# nrf9230_engb_flpr register map
Vendor: Nordic Semiconductor; Series: nRF92; File version: 1
Registers are 32-bit, read-write, reset 0x0 unless marked. A register's access mark holds for its fields unless they carry their own. Offsets are from the block's base; [hi:lo] are bit positions; {n}, {i} and the like mark numbered series; 'fields as' and 'values as' point back to an identical list.

## GLOBAL_WDT131 — Watchdog Timer 0
Base 0x5F92B000
Same registers: GLOBAL_WDT132 0x5F92C000
0x00 TASKS_START wo — Start WDT
  [0] TASKS_START
    1=Trigger task
0x04 TASKS_STOP wo — Stop WDT
  [0] TASKS_STOP
    1=Trigger task
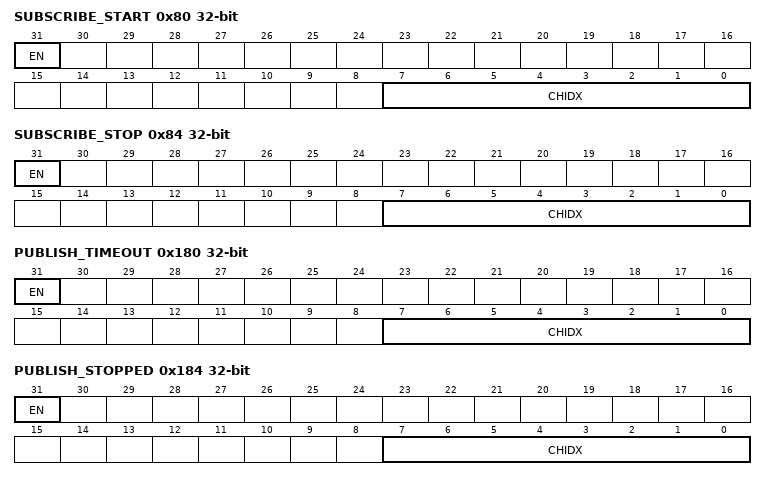
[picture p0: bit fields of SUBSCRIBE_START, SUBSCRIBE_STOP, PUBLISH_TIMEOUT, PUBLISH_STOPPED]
0x80 SUBSCRIBE_START — Subscribe configuration for task START
  [31] EN
    0=Disabled (Disable subscription); 1=Enabled (Enable subscription)
  [7:0] CHIDX — DPPI channel that task START will subscribe to
0x84 SUBSCRIBE_STOP — Subscribe configuration for task STOP
  [31] EN
    values as SUBSCRIBE_START.EN
  [7:0] CHIDX — DPPI channel that task STOP will subscribe to
0x100 EVENTS_TIMEOUT — Watchdog timeout
  [0] EVENTS_TIMEOUT
    0=NotGenerated (Event not generated); 1=Generated (Event generated)
0x104 EVENTS_STOPPED — Watchdog stopped
  [0] EVENTS_STOPPED
    values as EVENTS_TIMEOUT.EVENTS_TIMEOUT
0x180 PUBLISH_TIMEOUT — Publish configuration for event TIMEOUT
  [31] EN
    0=Disabled (Disable publishing); 1=Enabled (Enable publishing)
  [7:0] CHIDX — DPPI channel that event TIMEOUT will publish to
0x184 PUBLISH_STOPPED — Publish configuration for event STOPPED
  [31] EN
    values as PUBLISH_TIMEOUT.EN
  [7:0] CHIDX — DPPI channel that event STOPPED will publish to
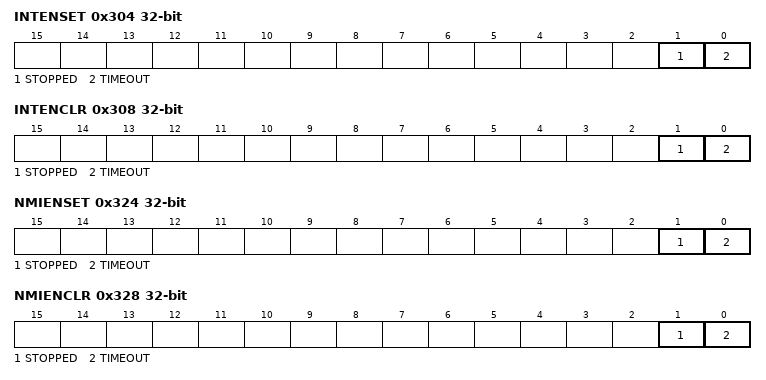
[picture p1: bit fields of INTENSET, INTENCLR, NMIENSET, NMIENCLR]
0x304 INTENSET — Enable interrupt
  [1] STOPPED — Write '1' to enable interrupt for event STOPPED
    on read: 0=Disabled (Read: Disabled); 1=Enabled (Read: Enabled) | on write: 1=Set (Enable)
  [0] TIMEOUT — Write '1' to enable interrupt for event TIMEOUT
    values as STOPPED
0x308 INTENCLR — Disable interrupt
  [1] STOPPED — Write '1' to disable interrupt for event STOPPED
    on read: 0=Disabled (Read: Disabled); 1=Enabled (Read: Enabled) | on write: 1=Clear (Disable)
  [0] TIMEOUT — Write '1' to disable interrupt for event TIMEOUT
    values as STOPPED
0x324 NMIENSET — Enable interrupt
  fields as INTENSET
0x328 NMIENCLR — Disable interrupt
  fields as INTENCLR
0x400 RUNSTATUS ro
  [0] RUNSTATUSWDT — Indicates whether or not WDT is running
    0=NotRunning (Watchdog is not running); 1=Running (Watchdog is running)
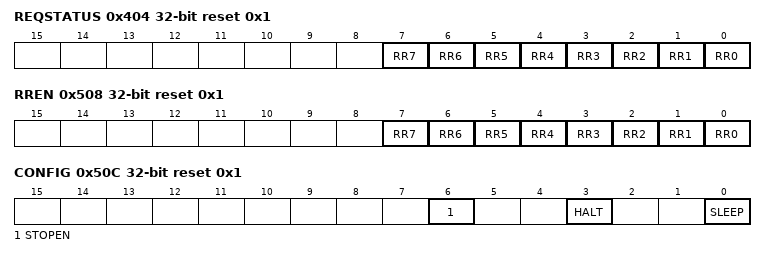
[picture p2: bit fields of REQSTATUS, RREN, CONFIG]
0x404 REQSTATUS ro reset 0x1 — Request status
  [n] RR{n} (n=0..7) — Request status for RR[{n}] register
    0=DisabledOrRequested (RR[{n}] register is not enabled, or are already requesting reload); 1=EnabledAndUnrequested (RR[{n}] register is enabled, and are not yet requesting reload)
0x504 CRV reset 0xFFFFFFFF — Counter reload value
  [31:0] CRV — Counter reload value in number of cycles of the 32.768 kHz clock
0x508 RREN reset 0x1 — Enable register for reload request registers
  [n] RR{n} (n=0..7) — Enable or disable RR[{n}] register
    0=Disabled (Disable RR[{n}] register); 1=Enabled (Enable RR[{n}] register)
0x50C CONFIG reset 0x1 — Configuration register
  [6] STOPEN — Allow stopping WDT
    0=Disable (Do not allow stopping WDT); 1=Enable (Allow stopping WDT)
  [3] HALT — Configure WDT to either be paused, or kept running, while the CPU is halted by the debugger
    0=Pause WDT while the CPU is halted by the debugger; 1=Run (Keep WDT running while the CPU is halted by the debugger)
  [0] SLEEP — Configure WDT to either be paused, or kept running, while the CPU is sleeping
    0=Pause WDT while the CPU is sleeping; 1=Run (Keep WDT running while the CPU is sleeping)
0x520 TSEN wo — Task stop enable
  [31:0] TSEN — Allow stopping WDT
    0x6E524635=Enable (Value to allow stopping WDT)
{0x600+4i} RR[{i}] (i=0..7) wo — Description collection: Reload request n
  [31:0] RR — Reload request register
    0x6E524635=Reload (Value to request a reload of the watchdog timer)

## GLOBAL_EGU130 — Event generator unit
Base 0x5F92D000
{0x0+4i} TASKS_TRIGGER[{i}] (i=0..15) wo — Description collection: Trigger n for triggering the corresponding TRIGGERED[n] event
  [0] TASKS_TRIGGER — Trigger n for triggering the corresponding TRIGGERED[n] event
    1=Trigger task
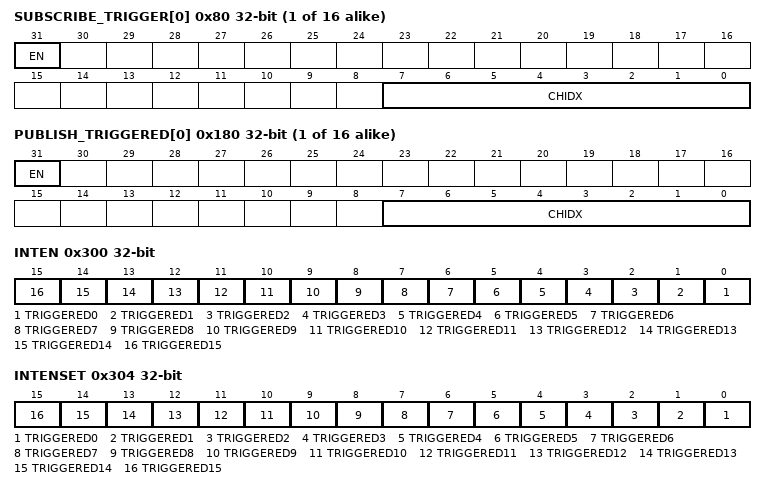
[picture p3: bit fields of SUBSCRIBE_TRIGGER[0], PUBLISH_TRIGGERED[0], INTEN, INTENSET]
{0x80+4i} SUBSCRIBE_TRIGGER[{i}] (i=0..15) — Description collection: Subscribe configuration for task TRIGGER[n]
  [31] EN
    0=Disabled (Disable subscription); 1=Enabled (Enable subscription)
  [7:0] CHIDX — DPPI channel that task TRIGGER[n] will subscribe to
{0x100+4i} EVENTS_TRIGGERED[{i}] (i=0..15) — Description collection: Event number n generated by triggering the corresponding TRIGGER[n] task
  [0] EVENTS_TRIGGERED — Event number n generated by triggering the corresponding TRIGGER[n] task
    0=NotGenerated (Event not generated); 1=Generated (Event generated)
{0x180+4i} PUBLISH_TRIGGERED[{i}] (i=0..15) — Description collection: Publish configuration for event TRIGGERED[n]
  [31] EN
    0=Disabled (Disable publishing); 1=Enabled (Enable publishing)
  [7:0] CHIDX — DPPI channel that event TRIGGERED[n] will publish to
0x300 INTEN — Enable or disable interrupt
  [all] fields
    0=Disabled; 1=Enabled
  [n] TRIGGERED{n} (n=0..15) — Enable or disable interrupt for event TRIGGERED[{n}]
0x304 INTENSET — Enable interrupt
  [all] fields
    on read: 0=Disabled (Read: Disabled); 1=Enabled (Read: Enabled) | on write: 1=Set (Enable)
  [n] TRIGGERED{n} (n=0..15) — Write '1' to enable interrupt for event TRIGGERED[{n}]
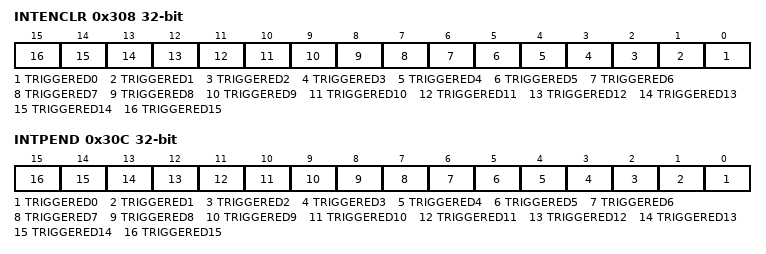
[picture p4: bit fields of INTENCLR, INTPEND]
0x308 INTENCLR — Disable interrupt
  [all] fields
    on read: 0=Disabled (Read: Disabled); 1=Enabled (Read: Enabled) | on write: 1=Clear (Disable)
  [n] TRIGGERED{n} (n=0..15) — Write '1' to disable interrupt for event TRIGGERED[{n}]
0x30C INTPEND ro — Pending interrupts
  [all] fields
    on read: 0=NotPending (Read: Not pending); 1=Pending (Read: Pending)
  [n] TRIGGERED{n} (n=0..15) — Read pending status of interrupt for event TRIGGERED[{n}]

## GLOBAL_TEMP — Temperature Sensor
Base 0x5F984000
0x00 TASKS_START wo — Start temperature measurement
  [0] TASKS_START
    1=Trigger task
0x04 TASKS_STOP wo — Stop temperature measurement
  [0] TASKS_STOP
    1=Trigger task
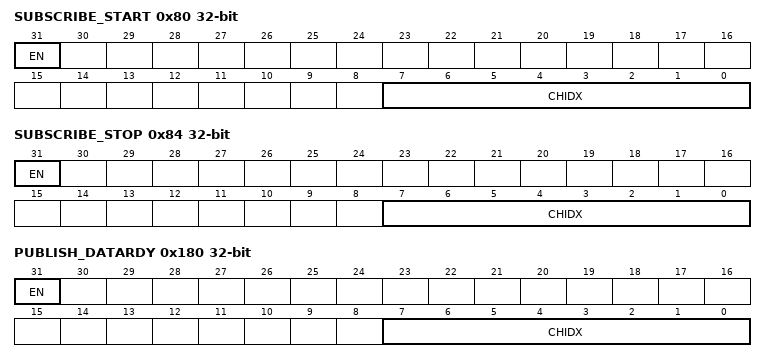
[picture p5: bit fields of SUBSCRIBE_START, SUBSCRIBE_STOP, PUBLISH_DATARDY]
0x80 SUBSCRIBE_START — Subscribe configuration for task START
  [31] EN
    0=Disabled (Disable subscription); 1=Enabled (Enable subscription)
  [7:0] CHIDX — DPPI channel that task START will subscribe to
0x84 SUBSCRIBE_STOP — Subscribe configuration for task STOP
  [31] EN
    values as SUBSCRIBE_START.EN
  [7:0] CHIDX — DPPI channel that task STOP will subscribe to
0x100 EVENTS_DATARDY — Temperature measurement complete, data ready
  [0] EVENTS_DATARDY
    0=NotGenerated (Event not generated); 1=Generated (Event generated)
0x180 PUBLISH_DATARDY — Publish configuration for event DATARDY
  [31] EN
    0=Disabled (Disable publishing); 1=Enabled (Enable publishing)
  [7:0] CHIDX — DPPI channel that event DATARDY will publish to
0x304 INTENSET — Enable interrupt
  [0] DATARDY — Write '1' to enable interrupt for event DATARDY
    on read: 0=Disabled (Read: Disabled); 1=Enabled (Read: Enabled) | on write: 1=Set (Enable)
0x308 INTENCLR — Disable interrupt
  [0] DATARDY — Write '1' to disable interrupt for event DATARDY
    on read: 0=Disabled (Read: Disabled); 1=Enabled (Read: Enabled) | on write: 1=Clear (Disable)
0x508 TEMP ro — Temperature in degC (0.25deg steps)
0x520 A0 reset 0x276 — Slope of 1st piece wise linear function
  [11:0] A0
0x524 A1 reset 0x324 — Slope of 2nd piece wise linear function
  [11:0] A1
0x528 A2 reset 0x3AB — Slope of 3rd piece wise linear function
  [11:0] A2
0x52C A3 reset 0x453 — Slope of 4th piece wise linear function
  [11:0] A3
0x530 A4 reset 0x49B — Slope of 5th piece wise linear function
  [11:0] A4
0x534 A5 reset 0x550 — Slope of 6th piece wise linear function
  [11:0] A5
0x538 A6 reset 0x67E — Slope of 7th piece wise linear function
  [11:0] A6
0x540 B0 reset 0xFA6 — y-intercept of 1st piece wise linear function
  [11:0] B0
0x544 B1 reset 0xF35 — y-intercept of 2nd piece wise linear function
  [11:0] B1
0x548 B2 reset 0xFAA — y-intercept of 3rd piece wise linear function
  [11:0] B2
0x54C B3 reset 0x7E — y-intercept of 4th piece wise linear function
  [11:0] B3
0x550 B4 reset 0xEA — y-intercept of 5th piece wise linear function
  [11:0] B4
0x554 B5 reset 0x1ED — y-intercept of 6th piece wise linear function
  [11:0] B5
0x558 B6 reset 0x378 — y-intercept of 7th piece wise linear function
  [11:0] B6
0x560 T0 reset 0xED — End point of 1st piece wise linear function
  [7:0] T0
0x564 T1 reset 0x13 — End point of 2nd piece wise linear function
  [7:0] T1
0x568 T2 reset 0x29 — End point of 3rd piece wise linear function
  [7:0] T2
0x56C T3 reset 0x3C — End point of 4th piece wise linear function
  [7:0] T3
0x570 T4 reset 0x44 — End point of 5th piece wise linear function
  [7:0] T4
0x574 T5 reset 0x53 — End point of 6th piece wise linear function
  [7:0] T5

## Notices in the file
Copyright (c) 2010 - 2024, Nordic Semiconductor ASA All rights reserved.
SPDX-License-Identifier: BSD-3-Clause
Redistribution and use in source and binary forms, with or without
modification, are permitted provided that the following conditions are met:
1. Redistributions of source code must retain the above copyright notice, this
list of conditions and the following disclaimer.
2. Redistributions in binary form must reproduce the above copyright
notice, this list of conditions and the following disclaimer in the
documentation and/or other materials provided with the distribution.
3. Neither the name of Nordic Semiconductor ASA nor the names of its
contributors may be used to endorse or promote products derived from this
software without specific prior written permission.
THIS SOFTWARE IS PROVIDED BY THE COPYRIGHT HOLDERS AND CONTRIBUTORS "AS IS"
AND ANY EXPRESS OR IMPLIED WARRANTIES, INCLUDING, BUT NOT LIMITED TO, THE
IMPLIED WARRANTIES OF MERCHANTABILITY, AND FITNESS FOR A PARTICULAR PURPOSE
ARE DISCLAIMED. IN NO EVENT SHALL NORDIC SEMICONDUCTOR ASA OR CONTRIBUTORS BE
LIABLE FOR ANY DIRECT, INDIRECT, INCIDENTAL, SPECIAL, EXEMPLARY, OR
CONSEQUENTIAL DAMAGES (INCLUDING, BUT NOT LIMITED TO, PROCUREMENT OF
SUBSTITUTE GOODS OR SERVICES; LOSS OF USE, DATA, OR PROFITS; OR BUSINESS
INTERRUPTION) HOWEVER CAUSED AND ON ANY THEORY OF LIABILITY, WHETHER IN
CONTRACT, STRICT LIABILITY, OR TORT (INCLUDING NEGLIGENCE OR OTHERWISE)
ARISING IN ANY WAY OUT OF THE USE OF THIS SOFTWARE, EVEN IF ADVISED OF THE
POSSIBILITY OF SUCH DAMAGE.
